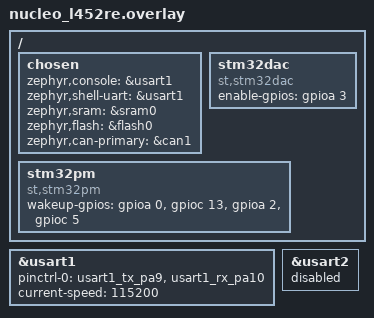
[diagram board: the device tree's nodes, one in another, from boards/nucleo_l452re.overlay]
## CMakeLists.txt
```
#-------------------------------------------------------------------------------
# Zephyr Example Application
#
# Copyright (c) 2021 
# SPDX-License-Identifier: Apache-2.0

cmake_minimum_required(VERSION 3.13.1)
find_package(Zephyr REQUIRED HINTS $ENV{ZEPHYR_BASE})

project(app LANGUAGES C VERSION 1.0.0)

configure_file(app_version.h.in ${CMAKE_BINARY_DIR}/app/include/app_version.h)
target_include_directories(app PRIVATE ${CMAKE_BINARY_DIR}/app/include include src)

FILE(GLOB app_sources src/*.cpp)
target_sources(app PRIVATE ${app_sources})
```

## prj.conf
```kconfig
# Copyright (c) 2021 Nordic Semiconductor ASA
# SPDX-License-Identifier: Apache-2.0
#
# This file contains selected Kconfig options for the application.

CONFIG_CPP=y

CONFIG_STM32LDAC=y

CONFIG_STM32LPM=y

#relocate the audio file to the flash
CONFIG_CODE_DATA_RELOCATION=n
CONFIG_HAVE_CUSTOM_LINKER_SCRIPT=y
CONFIG_CUSTOM_LINKER_SCRIPT="linker_arm_nocopy.ld"
```

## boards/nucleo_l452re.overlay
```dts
/*
 * Copyright (c) 2024 Farit N
 * SPDX-License-Identifier: Apache-2.0
 */

/* This devicetree overlay file will be automatically picked by the Zephyr
 * build system when building the sample for the nucleo_l452re board. It shows
 * how the example-application can be built on sample boards already provided
 * by Zephyr.
 */

/ {
    chosen {
        zephyr,console = &usart1;
        zephyr,shell-uart = &usart1;
        zephyr,sram = &sram0;
        zephyr,flash = &flash0;
        zephyr,can-primary = &can1;
    };

};

&usart1 {
    pinctrl-0 = <&usart1_tx_pa9 &usart1_rx_pa10>;
    pinctrl-names = "default";
    current-speed = <115200>;
    status = "okay";
};

&usart2 {
    status = "disabled";
};

/ {
    stm32dac {
        compatible = "st,stm32dac";
        enable-gpios = <&gpioa 3 0>;
    };
};

/ {
    stm32pm {
        compatible = "st,stm32pm";
        wakeup-gpios = <&gpioa 0 0>, 
            <&gpioc 13 0>, 
            <&gpioa 2 0>, 
            <&gpioc 5 0>; 
    };
};
```

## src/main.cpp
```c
/*
 * Copyright (c) 2023 Farit N
 * SPDX-License-Identifier: Apache-2.0
 */

#include <zephyr/kernel.h>

#include "app_version.h"

#include <zephyr/logging/log.h>
LOG_MODULE_REGISTER(main, LOG_LEVEL_INF);

#include <zephyr/device.h>
#include <zephyr/devicetree.h>
#include <zephyr/drivers/gpio.h>

#include <zephyr/sys/printk.h>

#include <zephyr/pm/device.h>
#include <zephyr/pm/state.h>

#include "GongAudio.h"
#include "GongPlayer.h"
#include "GongPm.h"


int main(void)
{

    //power management
    GongPm pm;
    int wakeupPin = pm.getWakeupPin();

    //how many times to repeat the signal if it's active
    const uint8_t repeatTimes = 5;
    //how many minutes to wait silently after a sound stops 
    //if a wakeup pin is still active
    const uint8_t waitSilentlyMinutes = 15;

    //if the microprocessor has been awaken by a wakeup pin
    if (wakeupPin >= 0) {
        for (int i = 0; i < repeatTimes; i++) {
            GongPlayer player;
            player.play(wakeupPin);

            if (pm.isWakeupPinActive() == 0) {
                break;
            }

            printk("Repeated the sound\n");
            
            //still active, play again after a pause
            k_msleep(500);
        }

        //don't play an annoying sound, just wait
        for (int i = 0; i < waitSilentlyMinutes * 60; i++) {
            if (pm.isWakeupPinActive() == 0) {
                break;
            }
            
            printk("A wakeup pin is active, wait seconds: %u\n", i);

            //sleep for 1 second
            k_msleep(1000);
        }
    }

    //increase when you need to reprogram often
    //you can't reprogram a sleeping device
    k_msleep(100);

    pm.standby();

    return 0;
}
```

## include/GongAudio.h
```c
/*
 * The class that definies the audio signal
 * 
 */
#ifndef __GONG_AUDIO_H
#define __GONG_AUDIO_H

#include <zephyr/sys/printk.h>

#include <zephyr/device.h>

/**
 * Contains audio data in the WAV format stored in the flash
 */
class GongAudio
{
    public:
        //the single  note sound data array
        const static uint8_t singleSoundData[178460];

        //the three notes sound data
        //repeat three times without a delay
        const static uint8_t threeSoundData[134594];

};

#endif
```

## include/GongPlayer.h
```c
/*
 * The class that plays gong signals
 * 
 */
#ifndef __GONG_PLAYER_H
#define __GONG_PLAYER_H

#include <zephyr/sys/printk.h>
#include <zephyr/device.h>
#include <zephyr/devicetree.h>

#include <stm32_ll_pwr.h>

#include "GongAudio.h"
#include <driver_stm32dac.h>


class GongPlayer
{
    public:

        GongPlayer();

        /**
         * Plays a signal depending on the wakeup pin
         *
         * @param int32_t wakeupPin The wakeup pin
         */
        void play(int32_t wakeupPin);

    private:

        //the DAC device
        const struct device *dac;

        //play the Gong T1 sound
        void playT1();

        //play the Gong T2 sound
        void playT2();

        //play the Gong T3 sound
        void playT3();

        //play the Gong T4 sound
        void playT4();

};

#endif
```

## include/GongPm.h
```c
/*
 * The class for Power management
 * 
 */
#ifndef __GONG_PM_H
#define __GONG_PM_H

#include <zephyr/sys/printk.h>

#include <zephyr/device.h>
#include <zephyr/devicetree.h>
#include <zephyr/pm/device.h>
#include <zephyr/pm/state.h>

#include <driver_stm32pm.h>


class GongPm
{
    public:
        GongPm();

        /**
         * Gets the wakeup pin that has awaken the system
         */
        int32_t getWakeupPin();

        /**
         * Checks if the wakeup pin is still active
         */
        int isWakeupPinActive();

        /**
         * Puts the system into the standby mode
         */
        void standby();

    private:
        
        //the PM device
        const struct device *pm;


};

#endif
```

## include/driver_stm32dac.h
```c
/*
 * Copyright (c) 2023 Farit
 *
 * SPDX-License-Identifier: Apache-2.0
 */

/**
 * @file
 * @brief STM32 DAC public API header file.
 */

#ifndef ZEPHYR_INCLUDE_DRIVERS_STM32DAC_H_
#define ZEPHYR_INCLUDE_DRIVERS_STM32DAC_H_

#include <zephyr/device.h>

#ifdef __cplusplus
extern "C" {
#endif

/**
 * @brief STM32 DAC driver APIs
 * @defgroup dac_interface DAC driver APIs
 * @ingroup io_interfaces
 * @{
 */


/*
 * Type definition of DAC API function for playing audio.
 */
typedef int (*stm32dac_api_play_audio)(const struct device *dev,
    uint8_t const* audio_data, const uint16_t play_times, const uint16_t play_delay);


/*
 * Type definition of STM32 DAC API function for stopping the DAC.
 */
typedef int (*stm32dac_api_stop)(const struct device *dev);


/*
 * STM32 DAC driver API
 *
 * This is the mandatory API any DAC driver needs to expose.
 */
__subsystem struct stm32dac_driver_api {
    stm32dac_api_play_audio play_audio;
    stm32dac_api_stop stop;
};

/**
 * @endcond
 */

/**
 * @brief Play audio data in the WAV format via DAC 
 *
 * @param dev         Pointer to the device structure for the driver instance
 * @param audio_data  Audio data in the WAV format
 * @param play_times  How many times to play the audio
 * @param play_delay  The delay before the next play 
 *
 * @retval 0        On success.
 * @retval -EINVAL  If a parameter with an invalid value has been provided.
 */
static inline int stm32dac_play_audio(const struct device *dev, uint8_t const* audio_data, 
    const uint16_t play_times, const uint16_t play_delay)
{
    const struct stm32dac_driver_api *api = (const struct stm32dac_driver_api *)dev->api;

    return api->play_audio(dev, audio_data, play_times, play_delay);
}

/**
 * @brief Stops the DAC 
 *
 * @param dev         Pointer to the device structure for the driver instance.
 *
 * @retval 0        On success.
 * @retval -EINVAL  If a parameter with an invalid value has been provided.
 */
static inline int stm32dac_stop(const struct device *dev)
{
    const struct stm32dac_driver_api *api = (const struct stm32dac_driver_api *)dev->api;

    return api->stop(dev);
}


/**
 * @}
 */

#ifdef __cplusplus
}
#endif

#endif  /* ZEPHYR_INCLUDE_DRIVERS_STM32DAC_H_ */
```

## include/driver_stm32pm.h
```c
/*
 * Copyright (c) 2023 Farit
 *
 * SPDX-License-Identifier: Apache-2.0
 */

/**
 * @file
 * @brief STM32 Power Management public API header file.
 */

#ifndef ZEPHYR_INCLUDE_DRIVERS_STM32PM_H_
#define ZEPHYR_INCLUDE_DRIVERS_STM32PM_H_

#include <zephyr/device.h>

#ifdef __cplusplus
extern "C" {
#endif

/**
 * @brief STM32 PM driver APIs
 * @defgroup pm_interface PM driver APIs
 * @ingroup io_interfaces
 * @{
 */

/**
 * @brief Get the wakeup pin that caused the processor to exit from the Standby mode
 *
 * @return int The ID of the wakeup pin
 */
typedef int32_t (*stm32pm_api_wakeup_pin_get)(const struct device *dev);

/**
 * @brief Check if the wakeup pin is still active
 *
 * @return int Active or not
 */
typedef int (*stm32pm_api_wakeup_pin_active)(const struct device *dev);


/**
 * @brief Put processor into a power state.
 *
 * This function implements the SoC specific details necessary
 * to put the processor into available power states.
 *
 * @param state Power state.
 * @param substate_id Power substate id.
 */

typedef int (*stm32pm_api_state_set)(const struct device *dev, enum pm_state state, uint8_t substate_id);


/*
 * STM32 PM driver API
 *
 * This is the mandatory API any STM32PM driver needs to expose.
 */
__subsystem struct stm32pm_driver_api {
    stm32pm_api_wakeup_pin_get wakeup_pin_get;
    stm32pm_api_wakeup_pin_active wakeup_pin_active;
    stm32pm_api_state_set state_set;
};

/**
 * @endcond
 */

/**
 * @brief Put processor into a power state.
 *
 * This function implements the SoC specific details necessary
 * to put the processor into available power states.
 *
 * @param state Power state.
 * @param substate_id Power substate id.
 * @retval 0        On success.
 * @retval -EINVAL  If a parameter with an invalid value has been provided.
 */
static inline int stm32pm_state_set(const struct device *dev, enum pm_state state, uint8_t substate_id)
{
    const struct stm32pm_driver_api *api = (const struct stm32pm_driver_api *)dev->api;

    return api->state_set(dev, state, substate_id);
}

/**
 * @brief Gets the wakeup pin that awaken the system
 *
 *
 * @retval int The number of the wakeup pin
 */
static inline int stm32pm_wakeup_pin_get(const struct device *dev)
{
    const struct stm32pm_driver_api *api = (const struct stm32pm_driver_api *)dev->api;

    return api->wakeup_pin_get(dev);
}

/**
 * @brief If the wakeup pin that has awaken the system is still active
 *
 *
 * @retval int Active or not
 */
static inline int stm32pm_wakeup_pin_active(const struct device *dev)
{
    const struct stm32pm_driver_api *api = (const struct stm32pm_driver_api *)dev->api;

    return api->wakeup_pin_active(dev);
}


/**
 * @}
 */

#ifdef __cplusplus
}
#endif

#endif  /* ZEPHYR_INCLUDE_DRIVERS_STM32PM_H_ */
```

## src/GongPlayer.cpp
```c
#include <GongPlayer.h>

GongPlayer::GongPlayer()
{
    dac = DEVICE_DT_GET(DT_COMPAT_GET_ANY_STATUS_OKAY(st_stm32dac));
    
    if (!dac) {
        printk("Device STM32DAC not found.\n");
    }

}

void GongPlayer::play(int32_t wakeupPin)
{
    printk("wakeupPin in play: %d\n", wakeupPin);

    switch(wakeupPin) {
        case LL_PWR_WAKEUP_PIN1:
            playT1();
            break;
        case LL_PWR_WAKEUP_PIN4:
            playT2();
            break;
        case LL_PWR_WAKEUP_PIN2:
            playT3();
            break;
        case LL_PWR_WAKEUP_PIN5:
            playT4();
            break;

        default:
            break;
    }

    //disables the amplifier
//    stm32dac_stop(dac);
}

void GongPlayer::playT1()
{
    printk("Playing T1 signal\n");

    stm32dac_play_audio(dac, GongAudio::threeSoundData, 1, 30);
}

void GongPlayer::playT2()
{
    printk("Playing T2 signal\n");

    stm32dac_play_audio(dac, GongAudio::singleSoundData, 1, 30);
}

void GongPlayer::playT3()
{
    printk("Playing T3 signal\n");

    stm32dac_play_audio(dac, GongAudio::singleSoundData, 1, 30);
}

void GongPlayer::playT4()
{
    printk("Playing T4 signal\n");

}
```

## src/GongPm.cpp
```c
#include <GongPm.h>

GongPm::GongPm()
{

    printk("\nGet device stm32lpm\n");
    pm = DEVICE_DT_GET(DT_COMPAT_GET_ANY_STATUS_OKAY(st_stm32pm));
    
    if (!pm) {
        printk("Device STM32PM not found.\n");
        return;
    }

}


/**
 * Gets the wakeup pin that has awaken the system
 */
int32_t GongPm::getWakeupPin()
{
    int wakeupPin = stm32pm_wakeup_pin_get(pm);
    printk("wakeupPin: %d\n", wakeupPin);

    return wakeupPin;
}

/**
 * Checks if the wakeup pin is still active
 */
int GongPm::isWakeupPinActive()
{
    int isActive = stm32pm_wakeup_pin_active(pm);
    printk("Is WakeupPin active: %d\n", isActive);

    return isActive;
}


/**
 * Puts the system into the standby mode
 */
void GongPm::standby()
{
    stm32pm_state_set(pm, PM_STATE_STANDBY, 0);
}
```
